# avsbus_controller: IP-XACT component
VLNV tenstorrent.com:ocah:avsbus_controller:1.0

## Address spaces and blocks
avsbus_controller_mmap.avsbus_controller: base 'h0, range 'h5c, width 32

## Registers
Registers are 32-bit, read-only, reset 0x0 unless marked. A register's access mark holds for its fields unless they carry their own. Offsets are from the block's base; lines under a group give offsets from that group; [hi:lo] are bit positions; {n}, {i} and the like mark numbered series; 'fields as' and 'values as' point back to an identical list; <NAME> marks a mode.

## avsbus_controller_mmap.avsbus_controller — Command, readback, status, and interrupt registers for the AVSBus (PMBus V1.3 Part III) controller.
Base 0x00000000
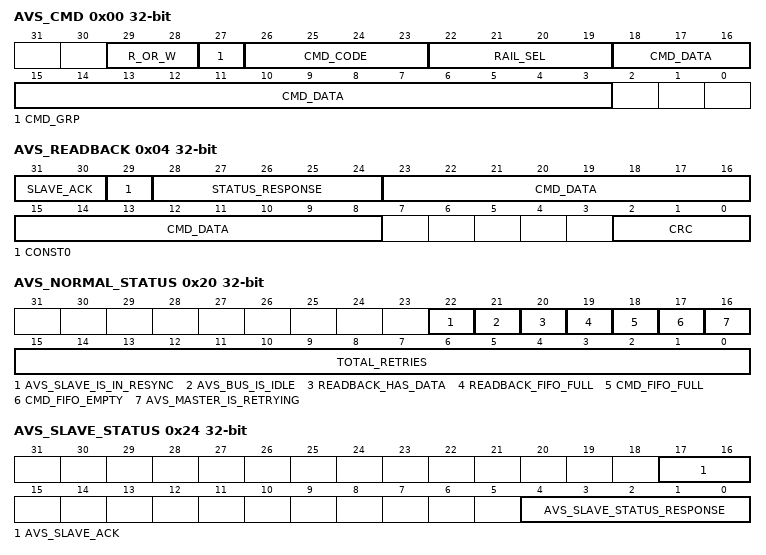
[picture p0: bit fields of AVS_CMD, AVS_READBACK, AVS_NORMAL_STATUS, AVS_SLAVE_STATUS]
0x00 AVS_CMD wo — The command+data to be transferred to the AVS bus
  [29:28] R_OR_W — Read or write type: [list] [*]0x0 - Commit Write [*]0x1 - Hold Write [*]0x2 - Reserved [*]0x3 - Read [/list]
  [27] CMD_GRP — Command group: Set to 1 for manufacturer-specific Command Code (cmd_code), otherwise 0
  [26:23] CMD_CODE — Command Code (For cmd_group=0. For cmd_group=1, this is manufacturer-specific): [list] [*]0x0 - Target Rail Voltage Read/Write [*]0x1 - Vout Transition Rate Read/Write [*]0x2 - Rail Current Read [*]0x3 - Temperature Read [*]0x4 - Force Voltage Reset (Requires wr_cmd_data=0x0) [*]0x5 - Power Mode Read/Write [*]0xe - AVSBus Status Read/Write [*]0xf - AVSBus Version Read [/list]
  [22:19] RAIL_SEL — Rail Select: 0x0 - Rail 0 0x1 - Rail 1 0xf - Broadcast
  [18:3] CMD_DATA — Write Cmd Data. Formats: [list] [*]Voltage (cmd_code 0x0): 16-bit unsigned int, 1LSB=1mV [*]Transition Rate (cmd_code 0x1): [list] [*]MSByte: Rise Rate, 8-bit unsigned int, 1LSB=1mV/us [*]LSByte: Fall Rate, 8-bit unsigned int, 1LSB=1mV/us [/list] [*]Reset Voltage (cmd_code 0x4): 16-bits, all zeroes [*]Power Mode (cmd_code 0x5): 3-bits, LSB aligned: [list] [*]0x0 - Maximum Efficiency [*]0x3 - Maximum Power [*]0x4-0x7 - Manufacturer-specific [/list] [*]AVSBus Status (cmd_code 0xe): 16-bits, encoded per AVS Spec [*]AVSBus Version (cmd_code 0xf): 4 bits encoded per AVS Spec, LSB-aligned [*]For read cmd_code's, this is 0xffff [/list]
0x04 AVS_READBACK — Response data from AVS slave device (updated in response to both AVS read and write commands). Reading this register causes the AVS response readback fifo pointer to advance.
  [31:30] SLAVE_ACK read-modifies — Indicates whether command executed or not - codes 0x1 and 0x2 trigger automatic retries by hardware: [list] [*]0x0: Action Performed [*]0x1: Good CRC received but resource unavailable - hardware will retry [*]0x2: Bad CRC received - hardware will retry [*]0x3: Good CRC received but bad data, data type or selector - no hardware retry [/list]
  [29] CONST0 read-modifies — Frame-valid bit of the slave response sub-frame: 0 in a valid frame, 1 when the slave did not respond
  [28:24] STATUS_RESPONSE read-modifies — 5-bit field indicating general condition of the slave, per AVS spec StatusReponse field: [list] [*]bit 4: VDone - AND of all VDone bits of active rails [*]bit 3: StatusAlert - Indicates potential status issue, requiring AVSBus Status read cmd for details [*]bit 2: AVS_Control - 1 if ABSBus is controlling at least 1 device output, 0 otherwise. [*]bit 1: MfrSpcfc_Stts1 - Manufacturer-specific [*]bit 0: MfrSpcfc_Stts2 - Manufacturer-specific [/list]
  [23:8] CMD_DATA read-modifies — Read Cmd Data. Format depends on cmd_code in previous master subframe:[list] [*]Voltage (cmd_code 0x0): 16-bit unsigned int, 1LSB=1mV [*]Transition Rate (cmd_code 0x1): [list] [*]MSByte: Rise Rate, 8-bit unsigned int, 1LSB=1mV/us [*]LSByte: Fall Rate, 8-bit unsigned int, 1LSB=1mV/us [/list] [*]Current (cmd_mode 0x2): 16-bit unsigned, 1LSB=10mA [*]Temperature (cmd_code 0x3): 16-bit signed, 1LSB=0.1degC [*]Power Mode (cmd_code 0x5): 3-bits, LSB aligned: [list] [*]0x0 - Maximum Efficiency [*]0x3 - Maximum Power [*]0x4-0x7 - Manufacturer-specific [/list] [*]AVSBus Status (cmd_code 0xe): 16-bits, encoded per AVS Spec [*]AVSBus Version (cmd_code 0xf): 4 bits encoded per AVS Spec, LSB-aligned [*]If master issued a write (rw!=0x3) in previous master subframe, this field is 0xffff [/list]
  [2:0] CRC read-modifies — The CRC-3 code received from slave
0x08 AVS_DEBUG_READBACK reset 0xFFFFFFFF — This register mirrors the AVS_READBACK register, but reading it does NOT affect the AVS readback fifo pointer. Provided for debug purposes.
  [31:0] AVS_SLAVE_SUBFRAME — The current top-of-fifo AVS slave response sub-frame in the readback fifo
0x0C AVS_LATEST_SLAVE_SUBFRAME — This register contains the most recently received subframe from the AVS slave, bypassing the AVS readback fifo. It is provided so that APB can see the current slave StatusResponse and SlaveAck settings in a timely fashion, since the status data from the next entry in the readback fifo might have considerable latency relative to when it was initially received from the AVS Slave.
  [31:0] AVS_SLAVE_SUBFRAME — The most recently received AVS slave response sub-frame
0x20 AVS_NORMAL_STATUS — Various Status bits indicating normal operating conditions for APB2AVS bridge block. These all have corresponding maskable bits in the AVS_INTERRUPT register
  [22] AVS_SLAVE_IS_IN_RESYNC — Indicates that the AVS master is issuing a slave resync operation (35 AVS clock cycles of holding mdata high)
  [21] AVS_BUS_IS_IDLE — Indicates that neither AVS master nor slave is currently driving a transaction on the AVS bus
  [20] READBACK_HAS_DATA — Indicates AVS_READBACK register has data ready to read on APB
  [19] READBACK_FIFO_FULL — Indicates read-back fifo is full - no new AVS commands will be launched until space is freed by an AVS_READBACK access
  [18] CMD_FIFO_FULL — Indicates AVS_CMD fifo is full - any additional APB writes to AVS_CMD will be dropped until the AVS bus can accept the next command, thus freeing space in the cmd fifo
  [17] CMD_FIFO_EMPTY — Indicates AVS_CMD fifo is empty
  [16] AVS_MASTER_IS_RETRYING — Master is currently in the middle of retrying a failed command
  [15:0] TOTAL_RETRIES — Total number of retries attempted by the AVS Master
0x24 AVS_SLAVE_STATUS — Contains the most recent status feedback from the AVS slave device
  [17:16] AVS_SLAVE_ACK — The SlaveAck bits of the most recent slave subframe received: [list] [*]00: Action Performed [*]01:Good CRC received by resource unavailable. No action performed (triggers retry) [*]10: Bad CRC received (triggers retry) [*]11: Good CRC received bit bad data, data type, or selector. No action performed [/list]
  [4:0] AVS_SLAVE_STATUS_RESPONSE — The 5-bit Slave StatusResponse of the most recent slave subframe received, indicating the general condition of the slave, per AVS spec StatusReponse field: [list] [*]bit 4: VDone - AND of all VDone bits of active rails [*]bit 3: StatusAlert - Indicates potential status issue, requiring AVSBus Status read cmd for details [*]bit 2: AVS_Control - 1 if ABSBus is controlling at least 1 device output, 0 otherwise. [*]bit 1: MfrSpcfc_Stts1 - Manufacturer-specific [*]bit 0: MfrSpcfc_Stts2 - Manufacturer-specific [/list]
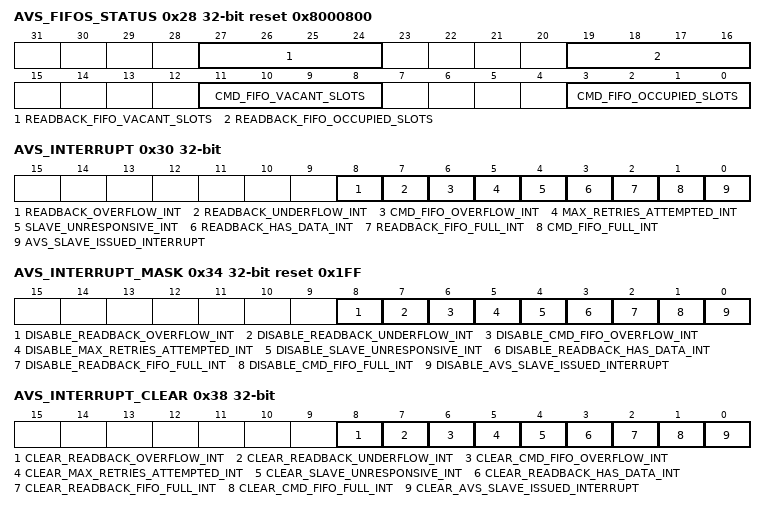
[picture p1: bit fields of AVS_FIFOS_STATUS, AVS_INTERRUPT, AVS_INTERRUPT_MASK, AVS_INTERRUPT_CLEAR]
0x28 AVS_FIFOS_STATUS reset 0x8000800 — Contains the number of occupied and vacant slots in the AVS master's command and readback FIFOs
  [27:24] READBACK_FIFO_VACANT_SLOTS — Number of vacant slots in the readback FIFO. The field has no storage; with the FIFO empty after reset it reads the READBACK_FIFO_DEPTH parameter, 8 by default, and the reset value is that default. The 4-bit field holds depths up to 15.
  [19:16] READBACK_FIFO_OCCUPIED_SLOTS — Number of occupied slots in the readback FIFO
  [11:8] CMD_FIFO_VACANT_SLOTS — Number of vacant slots in the command FIFO. The field has no storage; with the FIFO empty after reset it reads the COMMAND_FIFO_DEPTH parameter, 8 by default, and the reset value is that default. The 4-bit field holds depths up to 15.
  [3:0] CMD_FIFO_OCCUPIED_SLOTS — Number of occupied slots in the command FIFO
0x30 AVS_INTERRUPT — Interrupt register - A '1' indicates an interrupt has occurred for that bit. To clear the interrupt bit, write to the corresponding field in the AVS_INTERRUPT_CLEAR register.
  [8] READBACK_OVERFLOW_INT — Indicates that the response from AVS slave could not be written to readback FIFO due to it being full => response was dropped
  [7] READBACK_UNDERFLOW_INT — Indicates that an APB read on the AVS_READBACK reg occurred when the readback fifo was empty (AVS_NORMAL_STATUS:readback_has_data=0)
  [6] CMD_FIFO_OVERFLOW_INT — Indicates that an APB write to AVS_CMD was attempted when the the command fifo was already full - the command is dropped
  [5] MAX_RETRIES_ATTEMPTED_INT — Indicates that the AVS Master failed to receive a non-failure acknowledgement from the Slave after a command was retried the maximum allowable number of times (as determined by AVS_CFG_0:max_retries)
  [4] SLAVE_UNRESPONSIVE_INT — Indicates the AVS Slave device is not responding to command subframes from the Master
  [3] READBACK_HAS_DATA_INT — Indicates AVS_READBACK register has data ready to read on APB
  [2] READBACK_FIFO_FULL_INT — Indicates read-back fifo is full - no new AVS commands will be launched until space is freed by an AVS_READBACK access
  [1] CMD_FIFO_FULL_INT — Indicates AVS_CMD fifo is full - any additional APB writes to AVS_CMD will be dropped until the AVS bus can accept the next command, thus freeing space in the cmd fifo
  [0] AVS_SLAVE_ISSUED_INTERRUPT — Indicates the AVS slave has signaled an interrupt
0x34 AVS_INTERRUPT_MASK rw reset 0x1FF — Interrupt mask register - Determines which AVS_INTERRUPT bits can trigger an interrupt
  [8] DISABLE_READBACK_OVERFLOW_INT — Disable readback_overflow interrupt
  [7] DISABLE_READBACK_UNDERFLOW_INT — Disable readback_underflow interrupt
  [6] DISABLE_CMD_FIFO_OVERFLOW_INT — Disable cmd_fifo_overflow interrupt
  [5] DISABLE_MAX_RETRIES_ATTEMPTED_INT — Disable max_retries_attempted interrupt
  [4] DISABLE_SLAVE_UNRESPONSIVE_INT — Disable slave_unresponsive interrupt
  [3] DISABLE_READBACK_HAS_DATA_INT — Disable readback_has_data interrupt
  [2] DISABLE_READBACK_FIFO_FULL_INT — Disable readback_fifo_full interrupt
  [1] DISABLE_CMD_FIFO_FULL_INT — Disable cmd_fifo_full interrupt
  [0] DISABLE_AVS_SLAVE_ISSUED_INTERRUPT — Disable notification of AVS slave interrupt
0x38 AVS_INTERRUPT_CLEAR wo — Write 1 to clear corresponding interrupt bit
  [8] CLEAR_READBACK_OVERFLOW_INT — Clear readback_overflow interrupt
  [7] CLEAR_READBACK_UNDERFLOW_INT — Clear readback_underflow interrupt
  [6] CLEAR_CMD_FIFO_OVERFLOW_INT — Clear cmd_fifo_overflow interrupt
  [5] CLEAR_MAX_RETRIES_ATTEMPTED_INT — Clear max_retries_attempted interrupt
  [4] CLEAR_SLAVE_UNRESPONSIVE_INT — Clear slave_unresponsive interrupt
  [3] CLEAR_READBACK_HAS_DATA_INT — Clear readback_has_data interrupt
  [2] CLEAR_READBACK_FIFO_FULL_INT — Clear readback_fifo_full interrupt
  [1] CLEAR_CMD_FIFO_FULL_INT — Clear cmd_fifo_full interrupt
  [0] CLEAR_AVS_SLAVE_ISSUED_INTERRUPT
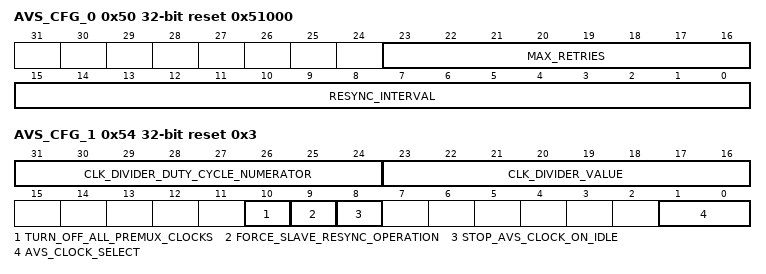
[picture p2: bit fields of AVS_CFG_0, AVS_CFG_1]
0x50 AVS_CFG_0 rw reset 0x51000 — Configuration register for APB2AVS bridge block
  [23:16] MAX_RETRIES — Maximum number of retries, after the original attempt, if an AVS command returns a fail status (either due to targeted resource being busy or CRC failure). A value of 0 disables retries and MAX_RETRIES_ATTEMPTED_INT.
  [15:0] RESYNC_INTERVAL — Interval between periodic slave resync operations on the AVS bus, in APB clock cycles counted from the end of the previous resync. The resulting request then crosses a 3-stage AVS clock synchronizer, and the resync starts once any frame in flight has completed.
0x54 AVS_CFG_1 rw reset 0x3 — Configuration register for APB2AVS bridge block
  [31:24] CLK_DIVIDER_DUTY_CYCLE_NUMERATOR — Determines the desired duty cycle of the divided clock (when avs_clock_select is set to select the divided APB clock or refclk clock). This value will be divided by 256 to determine the high-pulse percentage of the divided clock period. Depending on the clk_divider_value, it may not be possible to precisely achieve the desired duty cycle - in that case, the closest possible fit is used. If this is set to 0, a value of 1 will be assumed. Out of reset the divider uses a numerator of 0x80 (50%), not this field's reset value of 0. A write that changes this field or clk_divider_value loads both fields into the divider, so program both together.
  [23:16] CLK_DIVIDER_VALUE — Determines the divisor value used to generate the AVS clock (when avs_clock_select is set to select the divided APB clock or divided refclk clock). The duty cycle of the divided clock depends both on the clk_divider_value together with the clk_divider_duty_cycle_numerator value. A 50% duty cycle is only possible on even clk_divider_values with clk_divider_duty_cycle_numerator set to 128. This field requires a minimum value of 2 - for lower values, 2 will be assumed. Out of reset the divider uses a ratio of 4, not this field's reset value of 0. A write that changes this field or clk_divider_duty_cycle_numerator loads both fields into the divider, so program both together.
  [10] TURN_OFF_ALL_PREMUX_CLOCKS — Gate off all clocks entering the AVS clock mux - do this before changing the mux selection or changing the clock divider settings, then turn back on afterwards
  [9] FORCE_SLAVE_RESYNC_OPERATION — Force master to issue a slave resync (35 AVS clock cycles of holding the mdata signal high) at the next possible opportunity. The request crosses a 3-stage AVS clock synchronizer before the master sees it.
  [8] STOP_AVS_CLOCK_ON_IDLE — When the AVS bus is idle, gate the avs_clock from running. Restart it when there are new commands to be run. The master always issues a slave resync first when the clock restarts.
  [1:0] AVS_CLOCK_SELECT — Selects which clock to use for AVS Clock: [list] [*] 00: Use the APB clock directly as the AVS clock [*] 01: Use a divided version of APB clock as the AVS Clock. The clock divider settings are determined by AVS_CFG_1:clk_divider_value and AVS_CFG_1:clk_divider_duty_cycle_numerator [*] 10: Use the refclk clock directly as the AVS clock [*] 11: Use a divided version of refclk clock as the AVS Clock. The clock divider settings are determined by AVS_CFG_1:clk_divider_value and AVS_CFG_1:clk_divider_duty_cycle_numerator [/list]
0x58 AVS_CONFIG rw reset 0x1 — AVS Configuration Register
  [0] AVS_GPIO_ENABLE — Enable AVSBus connection to GPIOs. The effective sets OE of the GPIOs dedicated to avs_clock and avs_cdata to 1, sets IE of GPIO dedicated to avs_tdata to 1. By default, this is enabled as the AVSBus state machine immediately starts after reset deassertion.

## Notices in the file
SPDX-License-Identifier: Apache-2.0
SPDX-FileCopyrightText: 2026 Tenstorrent USA, Inc.
